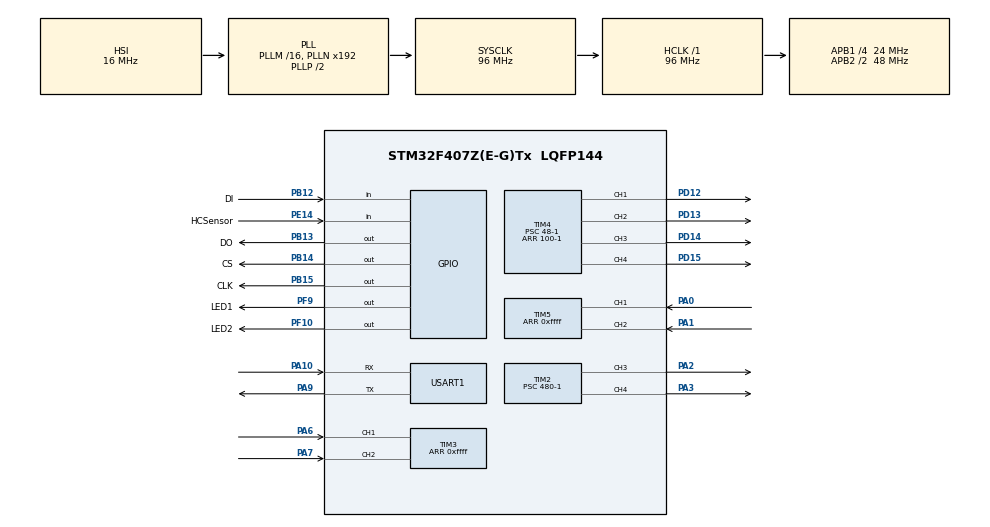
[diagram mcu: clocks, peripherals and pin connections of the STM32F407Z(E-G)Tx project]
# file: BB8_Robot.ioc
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Dma.Request0=USART1_RX
Dma.USART1_RX.0.Direction=DMA_PERIPH_TO_MEMORY
Dma.USART1_RX.0.FIFOMode=DMA_FIFOMODE_DISABLE
Dma.USART1_RX.0.Instance=DMA2_Stream2
Dma.USART1_RX.0.MemDataAlignment=DMA_MDATAALIGN_BYTE
Dma.USART1_RX.0.MemInc=DMA_MINC_ENABLE
Dma.USART1_RX.0.Mode=DMA_NORMAL
Dma.USART1_RX.0.PeriphDataAlignment=DMA_PDATAALIGN_BYTE
Dma.USART1_RX.0.PeriphInc=DMA_PINC_DISABLE
Dma.USART1_RX.0.Priority=DMA_PRIORITY_LOW
FREERTOS.Tasks01=TASK_LED,-2,128,Task_LED,Default,NULL,Dynamic,NULL,NULL;TASK_CONTROL,0,128,Task_Control,Default,NULL,Dynamic,NULL,NULL;TASK_TIM_2MS,2,512,Task_tim_2ms,Default,NULL,Dynamic,NULL,NULL
IWDG.Prescaler=IWDG_PRESCALER_32
IWDG.Reload=3000
Mcu.Family=STM32F4
Mcu.Name=STM32F407Z(E-G)Tx
Mcu.Package=LQFP144
NVIC.DMA2_Stream2_IRQn=true\:5\:0\:false\:false\:true\:true\:false
NVIC.PriorityGroup=NVIC_PRIORITYGROUP_4
NVIC.TIM1_UP_TIM10_IRQn=true\:0\:0\:false\:false\:true\:false\:false
NVIC.TimeBase=TIM1_UP_TIM10_IRQn
NVIC.TimeBaseIP=TIM1
PA0-WKUP.GPIO_ModeDefaultPP=GPIO_MODE_AF_OD
PA0-WKUP.Signal=S_TIM5_CH1
PA1.GPIO_ModeDefaultPP=GPIO_MODE_AF_OD
PA1.Signal=S_TIM5_CH2
PA10.Mode=Asynchronous
PA10.Signal=USART1_RX
PA2.Signal=S_TIM2_CH3
PA3.Signal=S_TIM2_CH4
PA6.GPIO_ModeDefaultPP=GPIO_MODE_AF_OD
PA6.Signal=S_TIM3_CH1
PA7.GPIO_ModeDefaultPP=GPIO_MODE_AF_OD
PA7.Signal=S_TIM3_CH2
PA9.Mode=Asynchronous
PA9.Signal=USART1_TX
PB12.GPIO_Label=DI
PB12.GPIO_PuPd=GPIO_PULLDOWN
PB12.Signal=GPIO_Input
PB13.GPIO_Label=DO
PB13.GPIO_PuPd=GPIO_PULLDOWN
PB13.Signal=GPIO_Output
PB14.GPIO_Label=CS
PB14.GPIO_ModeDefaultOutputPP=GPIO_MODE_OUTPUT_PP
PB14.GPIO_PuPd=GPIO_PULLDOWN
PB14.Signal=GPIO_Output
PB15.GPIO_Label=CLK
PB15.GPIO_PuPd=GPIO_PULLDOWN
PB15.Signal=GPIO_Output
PD12.Signal=S_TIM4_CH1
PD13.Signal=S_TIM4_CH2
PD14.Signal=S_TIM4_CH3
PD15.Signal=S_TIM4_CH4
PE14.GPIO_Label=HCSensor
PE14.Signal=GPIO_Input
PF10.GPIO_Label=LED2
PF10.GPIO_PuPd=GPIO_NOPULL
PF10.Signal=GPIO_Output
PF9.GPIO_Label=LED1
PF9.GPIO_PuPd=GPIO_NOPULL
PF9.Signal=GPIO_Output
PH0-OSC_IN.Mode=HSE-External-Oscillator
PH0-OSC_IN.Signal=RCC_OSC_IN
PH1-OSC_OUT.Mode=HSE-External-Oscillator
PH1-OSC_OUT.Signal=RCC_OSC_OUT
ProjectManager.HeapSize=0x200
ProjectManager.StackSize=0x400
ProjectManager.TargetToolchain=MDK-ARM V5
RCC.AHBFreq_Value=96000000
RCC.APB1CLKDivider=RCC_HCLK_DIV4
RCC.APB1Freq_Value=24000000
RCC.APB1TimFreq_Value=48000000
RCC.APB2CLKDivider=RCC_HCLK_DIV2
RCC.APB2Freq_Value=48000000
RCC.APB2TimFreq_Value=96000000
RCC.CortexFreq_Value=96000000
RCC.HCLKFreq_Value=96000000
RCC.HSE_VALUE=25000000
RCC.HSI_VALUE=16000000
RCC.LSE_VALUE=32768
RCC.SYSCLKFreq_VALUE=96000000
RCC.SYSCLKSource=RCC_SYSCLKSOURCE_PLLCLK
RCC.VCOOutputFreq_Value=192000000
SH.S_TIM2_CH3.0=TIM2_CH3,PWM Generation3 CH3
SH.S_TIM2_CH4.0=TIM2_CH4,PWM Generation4 CH4
SH.S_TIM3_CH1.0=TIM3_CH1,Encoder_Interface
SH.S_TIM3_CH2.0=TIM3_CH2,Encoder_Interface
SH.S_TIM4_CH1.0=TIM4_CH1,PWM Generation1 CH1
SH.S_TIM4_CH2.0=TIM4_CH2,PWM Generation2 CH2
SH.S_TIM4_CH3.0=TIM4_CH3,PWM Generation3 CH3
SH.S_TIM4_CH4.0=TIM4_CH4,PWM Generation4 CH4
SH.S_TIM5_CH1.0=TIM5_CH1,Encoder_Interface
SH.S_TIM5_CH2.0=TIM5_CH2,Encoder_Interface
TIM14.Period=1
TIM14.Prescaler=47
TIM2.Channel-PWM\ Generation3\ CH3=TIM_CHANNEL_3
TIM2.Channel-PWM\ Generation4\ CH4=TIM_CHANNEL_4
TIM2.Period=2000-1
TIM2.Prescaler=480-1
TIM3.EncoderMode=TIM_ENCODERMODE_TI12
TIM3.Period=0xffff
TIM4.Channel-PWM\ Generation1\ CH1=TIM_CHANNEL_1
TIM4.Channel-PWM\ Generation2\ CH2=TIM_CHANNEL_2
TIM4.Channel-PWM\ Generation3\ CH3=TIM_CHANNEL_3
TIM4.Channel-PWM\ Generation4\ CH4=TIM_CHANNEL_4
TIM4.Period=100-1
TIM4.Prescaler=48-1
TIM5.EncoderMode=TIM_ENCODERMODE_TI12
TIM5.Period=0xffff
USART1.StopBits=STOPBITS_1
USART1.VirtualMode=VM_ASYNC
VP_FREERTOS_VS_ENABLE.Mode=Enabled
VP_IWDG_VS_IWDG.Mode=IWDG_Activate
VP_SYS_VS_tim1.Mode=TIM1
VP_TIM14_VS_ClockSourceINT.Mode=Enable_Timer
board=custom

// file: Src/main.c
/**
  ******************************************************************************
  * @file           : main.c
  * @brief          : Main program body
  ******************************************************************************
  * This notice applies to any and all portions of this file
  * that are not between comment pairs USER CODE BEGIN and
  * USER CODE END. Other portions of this file, whether
  * inserted by the user or by software development tools
  * are owned by their respective copyright owners.
  *
  * Copyright (c) 2019 STMicroelectronics International N.V.
  * All rights reserved.
  *
  * Redistribution and use in source and binary forms, with or without
  * modification, are permitted, provided that the following conditions are met:
  *
  * 1. Redistribution of source code must retain the above copyright notice,
  *    this list of conditions and the following disclaimer.
  * 2. Redistributions in binary form must reproduce the above copyright notice,
  *    this list of conditions and the following disclaimer in the documentation
  *    and/or other materials provided with the distribution.
  * 3. Neither the name of STMicroelectronics nor the names of other
  *    contributors to this software may be used to endorse or promote products
  *    derived from this software without specific written permission.
  * 4. This software, including modifications and/or derivative works of this
  *    software, must execute solely and exclusively on microcontroller or
  *    microprocessor devices manufactured by or for STMicroelectronics.
  * 5. Redistribution and use of this software other than as permitted under
  *    this license is void and will automatically terminate your rights under
  *    this license.
  *
  * THIS SOFTWARE IS PROVIDED BY STMICROELECTRONICS AND CONTRIBUTORS "AS IS"
  * AND ANY EXPRESS, IMPLIED OR STATUTORY WARRANTIES, INCLUDING, BUT NOT
  * LIMITED TO, THE IMPLIED WARRANTIES OF MERCHANTABILITY, FITNESS FOR A
  * PARTICULAR PURPOSE AND NON-INFRINGEMENT OF THIRD PARTY INTELLECTUAL PROPERTY
  * RIGHTS ARE DISCLAIMED TO THE FULLEST EXTENT PERMITTED BY LAW. IN NO EVENT
  * SHALL STMICROELECTRONICS OR CONTRIBUTORS BE LIABLE FOR ANY DIRECT, INDIRECT,
  * INCIDENTAL, SPECIAL, EXEMPLARY, OR CONSEQUENTIAL DAMAGES (INCLUDING, BUT NOT
  * LIMITED TO, PROCUREMENT OF SUBSTITUTE GOODS OR SERVICES; LOSS OF USE, DATA,
  * OR PROFITS; OR BUSINESS INTERRUPTION) HOWEVER CAUSED AND ON ANY THEORY OF
  * LIABILITY, WHETHER IN CONTRACT, STRICT LIABILITY, OR TORT (INCLUDING
  * NEGLIGENCE OR OTHERWISE) ARISING IN ANY WAY OUT OF THE USE OF THIS SOFTWARE,
  * EVEN IF ADVISED OF THE POSSIBILITY OF SUCH DAMAGE.
  *
  ******************************************************************************
  */
#include "includes.h"

/* USER CODE BEGIN PV */
/* Private variables ---------------------------------------------------------*/

/* USER CODE END PV */

void SystemClock_Config(void);
void MX_FREERTOS_Init(void);

/* USER CODE BEGIN PFP */
/* Private function prototypes -----------------------------------------------*/

/* USER CODE END PFP */

int main(void)
{

  /* MCU Configuration----------------------------------------------------------*/

  /* Reset of all peripherals, Initializes the Flash interface and the Systick. */
  HAL_Init();

  /* Configure the system clock */
  SystemClock_Config();

  /* Initialize all configured peripherals */
  MX_GPIO_Init();
  MX_DMA_Init();
  MX_USART1_UART_Init();
  MX_TIM2_Init();
  MX_TIM14_Init();
  MX_IWDG_Init();
  MX_TIM4_Init();
  MX_TIM5_Init();
  MX_TIM3_Init();
  /* USER CODE BEGIN 2 */

  HAL_TIM_PWM_Start(&htim2,TIM_CHANNEL_3);
	HAL_TIM_PWM_Start(&htim4,TIM_CHANNEL_1);
	HAL_TIM_PWM_Start(&htim4,TIM_CHANNEL_2);
	HAL_TIM_PWM_Start(&htim4,TIM_CHANNEL_3);
	HAL_TIM_PWM_Start(&htim4,TIM_CHANNEL_4);

	HAL_TIM_Encoder_Start(&htim3, TIM_CHANNEL_ALL);
	HAL_TIM_Encoder_Start(&htim5, TIM_CHANNEL_ALL);
  /* USER CODE END 2 */

  /* Call init function for freertos objects (in freertos.c) */
  MX_FREERTOS_Init();

  /* Start scheduler */
  osKernelStart();

  /* We should never get here as control is now taken by the scheduler */

  /* Infinite loop */
  while (1)
  {

  }

}

void SystemClock_Config(void)
{

  RCC_OscInitTypeDef RCC_OscInitStruct;
  RCC_ClkInitTypeDef RCC_ClkInitStruct;

    /**Configure the main internal regulator output voltage
    */
  __HAL_RCC_PWR_CLK_ENABLE();

  __HAL_PWR_VOLTAGESCALING_CONFIG(PWR_REGULATOR_VOLTAGE_SCALE1);

    /**Initializes the CPU, AHB and APB busses clocks
    */
  RCC_OscInitStruct.OscillatorType = RCC_OSCILLATORTYPE_HSI|RCC_OSCILLATORTYPE_LSI;
  RCC_OscInitStruct.HSIState = RCC_HSI_ON;
  RCC_OscInitStruct.HSICalibrationValue = 16;
  RCC_OscInitStruct.LSIState = RCC_LSI_ON;
  RCC_OscInitStruct.PLL.PLLState = RCC_PLL_ON;
  RCC_OscInitStruct.PLL.PLLSource = RCC_PLLSOURCE_HSI;
  RCC_OscInitStruct.PLL.PLLM = 16;
  RCC_OscInitStruct.PLL.PLLN = 192;
  RCC_OscInitStruct.PLL.PLLP = RCC_PLLP_DIV2;
  RCC_OscInitStruct.PLL.PLLQ = 4;
  if (HAL_RCC_OscConfig(&RCC_OscInitStruct) != HAL_OK)
  {
    _Error_Handler(__FILE__, __LINE__);
  }

    /**Initializes the CPU, AHB and APB busses clocks
    */
  RCC_ClkInitStruct.ClockType = RCC_CLOCKTYPE_HCLK|RCC_CLOCKTYPE_SYSCLK
                              |RCC_CLOCKTYPE_PCLK1|RCC_CLOCKTYPE_PCLK2;
  RCC_ClkInitStruct.SYSCLKSource = RCC_SYSCLKSOURCE_PLLCLK;
  RCC_ClkInitStruct.AHBCLKDivider = RCC_SYSCLK_DIV1;
  RCC_ClkInitStruct.APB1CLKDivider = RCC_HCLK_DIV4;
  RCC_ClkInitStruct.APB2CLKDivider = RCC_HCLK_DIV2;

  if (HAL_RCC_ClockConfig(&RCC_ClkInitStruct, FLASH_LATENCY_3) != HAL_OK)
  {
    _Error_Handler(__FILE__, __LINE__);
  }

    /**Configure the Systick interrupt time
    */
  HAL_SYSTICK_Config(HAL_RCC_GetHCLKFreq()/1000);

    /**Configure the Systick
    */
  HAL_SYSTICK_CLKSourceConfig(SYSTICK_CLKSOURCE_HCLK);

  /* SysTick_IRQn interrupt configuration */
  HAL_NVIC_SetPriority(SysTick_IRQn, 15, 0);
}

void HAL_TIM_PeriodElapsedCallback(TIM_HandleTypeDef *htim)
{
  if (htim->Instance == TIM1) {
    HAL_IncTick();
  }
}

void _Error_Handler(char *file, int line)
{
  while(1)
  {
  }
}

/************************ (C) COPYRIGHT STMicroelectronics *****END OF FILE****/

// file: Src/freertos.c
/**
  ******************************************************************************
  * File Name          : freertos.c
  * Description        : Code for freertos applications
  ******************************************************************************
  * This notice applies to any and all portions of this file
  * that are not between comment pairs USER CODE BEGIN and
  * USER CODE END. Other portions of this file, whether
  * inserted by the user or by software development tools
  * are owned by their respective copyright owners.
  *
  * Copyright (c) 2019 STMicroelectronics International N.V.
  * All rights reserved.
  *
  * Redistribution and use in source and binary forms, with or without
  * modification, are permitted, provided that the following conditions are met:
  *
  * 1. Redistribution of source code must retain the above copyright notice,
  *    this list of conditions and the following disclaimer.
  * 2. Redistributions in binary form must reproduce the above copyright notice,
  *    this list of conditions and the following disclaimer in the documentation
  *    and/or other materials provided with the distribution.
  * 3. Neither the name of STMicroelectronics nor the names of other
  *    contributors to this software may be used to endorse or promote products
  *    derived from this software without specific written permission.
  * 4. This software, including modifications and/or derivative works of this
  *    software, must execute solely and exclusively on microcontroller or
  *    microprocessor devices manufactured by or for STMicroelectronics.
  * 5. Redistribution and use of this software other than as permitted under
  *    this license is void and will automatically terminate your rights under
  *    this license.
  *
  * THIS SOFTWARE IS PROVIDED BY STMICROELECTRONICS AND CONTRIBUTORS "AS IS"
  * AND ANY EXPRESS, IMPLIED OR STATUTORY WARRANTIES, INCLUDING, BUT NOT
  * LIMITED TO, THE IMPLIED WARRANTIES OF MERCHANTABILITY, FITNESS FOR A
  * PARTICULAR PURPOSE AND NON-INFRINGEMENT OF THIRD PARTY INTELLECTUAL PROPERTY
  * RIGHTS ARE DISCLAIMED TO THE FULLEST EXTENT PERMITTED BY LAW. IN NO EVENT
  * SHALL STMICROELECTRONICS OR CONTRIBUTORS BE LIABLE FOR ANY DIRECT, INDIRECT,
  * INCIDENTAL, SPECIAL, EXEMPLARY, OR CONSEQUENTIAL DAMAGES (INCLUDING, BUT NOT
  * LIMITED TO, PROCUREMENT OF SUBSTITUTE GOODS OR SERVICES; LOSS OF USE, DATA,
  * OR PROFITS; OR BUSINESS INTERRUPTION) HOWEVER CAUSED AND ON ANY THEORY OF
  * LIABILITY, WHETHER IN CONTRACT, STRICT LIABILITY, OR TORT (INCLUDING
  * NEGLIGENCE OR OTHERWISE) ARISING IN ANY WAY OUT OF THE USE OF THIS SOFTWARE,
  * EVEN IF ADVISED OF THE POSSIBILITY OF SUCH DAMAGE.
  *
  ******************************************************************************
  */

#include "includes.h"

osThreadId TASK_LEDHandle;
osThreadId TASK_CONTROLHandle;
osThreadId TASK_TIM_2MSHandle;

void Task_LED(void const * argument);
void Task_Control(void const * argument);
void Task_tim_2ms(void const * argument);

void MX_FREERTOS_Init(void); /* (MISRA C 2004 rule 8.1) */

/* Hook prototypes */

/* Init FreeRTOS */

void MX_FREERTOS_Init(void) {
  /* USER CODE BEGIN Init */
	InitGyroUart();
	InitLED();
  /* USER CODE END Init */

  /* Create the thread(s) */
  /* definition and creation of TASK_LED */
  osThreadDef(TASK_LED, Task_LED, osPriorityLow, 0, 128);
  TASK_LEDHandle = osThreadCreate(osThread(TASK_LED), NULL);

<<<<<<< HEAD
  /* definition and creation of TASK_CONTROL */
  osThreadDef(TASK_CONTROL, Task_Control, osPriorityNormal, 0, 128);
  TASK_CONTROLHandle = osThreadCreate(osThread(TASK_CONTROL), NULL);

  /* definition and creation of TASK_TIM_2MS */
  osThreadDef(TASK_TIM_2MS, Task_tim_2ms, osPriorityHigh, 0, 512);
  TASK_TIM_2MSHandle = osThreadCreate(osThread(TASK_TIM_2MS), NULL);
=======
  /* definition and creation of TASK_GRYO */
//  osThreadDef(TASK_GRYO, Task_GRYO, osPriorityNormal, 0, 256);
//  TASK_GRYOHandle = osThreadCreate(osThread(TASK_GRYO), NULL);

  /* definition and creation of TASK_SERVO */
  osThreadDef(TASK_SERVO, Task_Servo, osPriorityNormal, 0, 512);
  TASK_SERVOHandle = osThreadCreate(osThread(TASK_SERVO), NULL);

  /* definition and creation of TASK_PS2 */
  osThreadDef(TASK_PS2, Task_ps2, osPriorityHigh, 0, 512);
  TASK_PS2Handle = osThreadCreate(osThread(TASK_PS2), NULL);

  /* definition and creation of TASK_ENCODER */
//  osThreadDef(TASK_ENCODER, Task_encoder, osPriorityAboveNormal, 0, 256);
//  TASK_ENCODERHandle = osThreadCreate(osThread(TASK_ENCODER), NULL);
>>>>>>> master

}

/* Task_LED function */
//void Task_LED(void const * argument)
//{

//  /* USER CODE BEGIN Task_LED */
//////////  /* Infinite loop */
//////////  for(;;)
//////////  {
//////////    osDelay(1);
//////////  }
//  /* USER CODE END Task_LED */
//}

///* Task_Control function */
//void Task_Control(void const * argument)
//{
//  /* USER CODE BEGIN Task_Control */
//  /* Infinite loop */
//  for(;;)
//  {
//    osDelay(1);
//  }
//  /* USER CODE END Task_Control */
//}

///* Task_tim_2ms function */
//void Task_tim_2ms(void const * argument)
//{
//  /* USER CODE BEGIN Task_tim_2ms */
//  /* Infinite loop */
//  for(;;)
//  {
//    osDelay(1);
//  }
//  /* USER CODE END Task_tim_2ms */
//}

/************************ (C) COPYRIGHT STMicroelectronics *****END OF FILE****/
